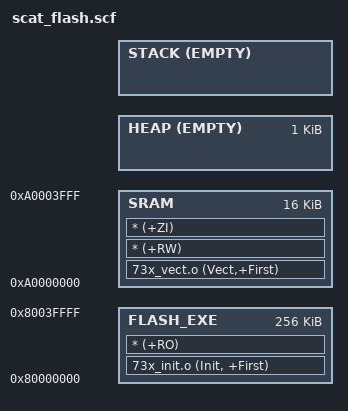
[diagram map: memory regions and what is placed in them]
;******************** (C) COPYRIGHT 2005 STMicroelectronics **************************/
;* File Name          : scat_flash.scf
;* Author             : MCD Application Team
;* Date First Issued  : 09/27/2005 :  V1.0
;* Description        : This file provides an example of a scatterloading descriptor
;*                    : file that defines one load region in the Embedded Flash
;*                    : and four execution regions.
;*************************************************************************************/
;* History:
;* 09/27/2005 :  V1.0
;*************************************************************************************/
; THE PRESENT SOFTWARE WHICH IS FOR GUIDANCE ONLY AIMS AT PROVIDING CUSTOMERS
; WITH  CODING INFORMATION REGARDING THEIR PRODUCTS IN ORDER FOR THEM TO SAVE TIME.
; AS A RESULT, STMICROELECTRONICS SHALL NOT BE HELD LIABLE FOR ANY DIRECT, INDIRECT
; OR CONSEQUENTIAL DAMAGES WITH RESPECT TO ANY CLAIMS ARISING FROM THE CONTENT
; OF SUCH SOFTWARE AND/OR THE USE MADE BY CUSTOMERS OF THE CODING INFORMATION
; CONTAINED HEREIN IN CONNECTION WITH THEIR PRODUCTS.
;*************************************************************************************/


; Embedded Flash (256/128/64Kbytes)
; The user has to change the flash memory length depending STR73xFxx devices

FLASH_LOAD 0x80000000  0x40000  ; 0x20000/0x10000
{

    FLASH_EXE 0x80000000  0x40000 ; 0x20000/0x10000  	
    {
         73x_init.o (Init, +First)
	     * (+RO)
    }

    ; Embedded RAM  (16Kbytes)

    SRAM 0xA0000000  0x4000
    {
	   73x_vect.o (Vect,+First)
	   * (+RW)
	   * (+ZI)	
    }
	
    ; Heap will grow just above ZI region :
    ; This Symbol is exported to "73x_init.s" file

    HEAP +0 EMPTY 0x400
    {	
    }

    ; Stack Base address exported to "73x_init.s" file ( Top of SRAM )

    STACK 0xA0004000 EMPTY -0x0
    {
    }
}

;******************* (C) COPYRIGHT 2005 STMicroelectronics ***********END OF FILE****;

